AUTOSAR XML (schema 00048)
package /MICROSAR/ComM_swc
  mode declaration group ComMMode: initial-mode=COMM_NO_COMMUNICATION
    mode COMM_NO_COMMUNICATION
    mode COMM_SILENT_COMMUNICATION
    mode COMM_FULL_COMMUNICATION
  data type mapping set ComMMode_DataTypeMappingSet: mode-request-type-map{implementation-data-type=ComM_ModeType, mode-group=ComMMode}  # Data Mapping for the Mode Declaration Group ComMMode.
package /MICROSAR/ComM_swc/DataTypes
  4 x impl type, all with category=TYPE_REFERENCE:
    ComM_ModeType: compu {0=COMM_NO_COMMUNICATION, 1=COMM_SILENT_COMMUNICATION, 2=COMM_FULL_COMMUNICATION}, range raw 0..3, implementation-data-type=uint8
    ComM_InhibitionStatusType: range raw 0..255, implementation-data-type=uint8
    ComM_UserHandleType: range raw 0..65535, implementation-data-type=uint16
    NetworkHandleType: range raw 0..255, implementation-data-type=uint8, type-emitter=ComM
package /MICROSAR/ComM_swc/Interfaces
  4 x client server interface, all with is-service=true, service-kind=COM-MANAGER:
    ComM_UserRequest
      4 x operation:
        RequestComMode: possible-error=[ComM_UserRequest/E_NOT_OK, E_MODE_LIMITATION]
          arg ComMode: type=ComM_ModeType, direction=IN
        GetCurrentComMode: possible-error=ComM_UserRequest/E_NOT_OK
          arg ComMode: type=ComM_ModeType, direction=OUT
        GetMaxComMode: possible-error=ComM_UserRequest/E_NOT_OK
          arg ComMode: type=ComM_ModeType, direction=OUT
        GetRequestedComMode: possible-error=ComM_UserRequest/E_NOT_OK
          arg ComMode: type=ComM_ModeType, direction=OUT
      4 x error:
        E_NOT_OK: error-code=1
        E_MODE_LIMITATION: error-code=2
        E_MULTIPLE_PNC_ASSIGNED: error-code=4
        COMM_E_NO_PNC_ASSIGNED: error-code=5
    ComM_ECUModeLimitation
      4 x operation, all with possible-error=ComM_ECUModeLimitation/E_NOT_OK:
        LimitECUToNoComMode
          arg Status: type=boolean, direction=IN
        ReadInhibitCounter
          arg CounterValue: type=uint16, direction=OUT
        ResetInhibitCounter
        SetECUGroupClassification
          arg Status: type=ComM_InhibitionStatusType, direction=IN
      error E_NOT_OK: error-code=1
    ComM_ChannelWakeUp
      operation PreventWakeUp: possible-error=ComM_ChannelWakeUp/E_NOT_OK
        arg Status: type=boolean, direction=IN
      operation GetInhibitionStatus: possible-error=ComM_ChannelWakeUp/E_NOT_OK
        arg Status: type=ComM_InhibitionStatusType, direction=OUT
      error E_NOT_OK: error-code=1
    ComM_ChannelLimitation
      operation LimitChannelToNoComMode: possible-error=ComM_ChannelLimitation/E_NOT_OK
        arg Status: type=boolean, direction=IN
      operation GetInhibitionStatus: possible-error=ComM_ChannelLimitation/E_NOT_OK
        arg Status: type=ComM_InhibitionStatusType, direction=OUT
      error E_NOT_OK: error-code=1
  mode switch interface ComM_CurrentMode: is-service=true, service-kind=COM-MANAGER
    mode group currentMode: type=ComMMode
package /MICROSAR/ComM_swc/ComponentTypes
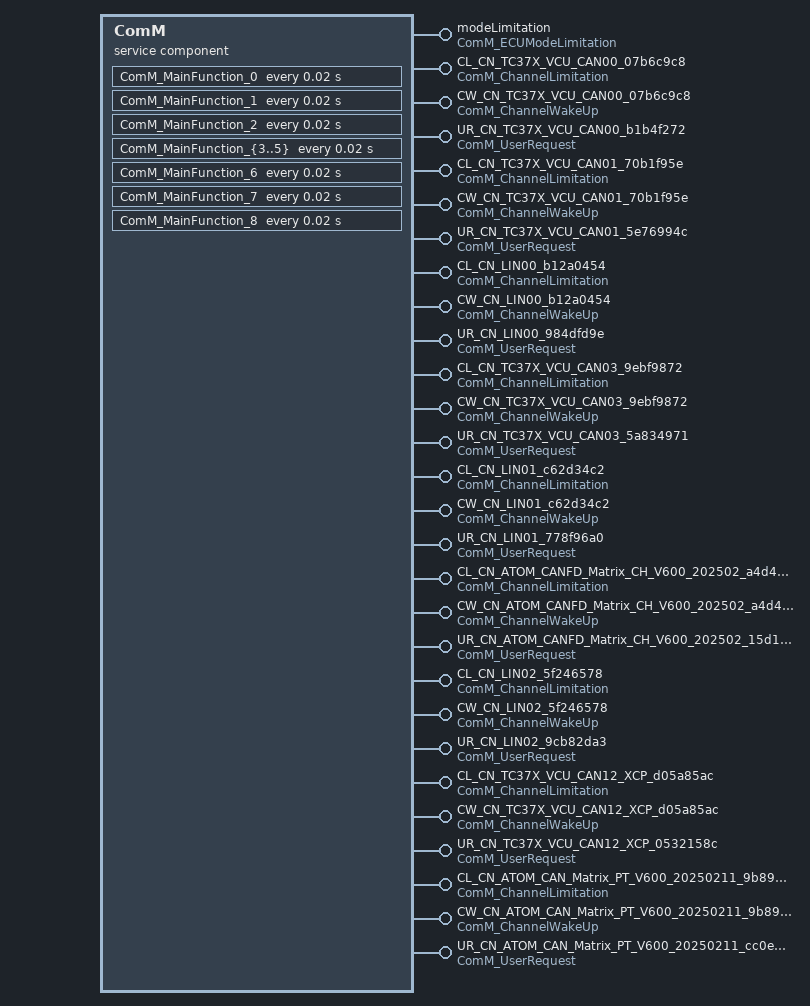
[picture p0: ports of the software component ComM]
  service sw component type ComM: category=SERVICE_COMPONENT
    28 x provide port:
      modeLimitation: provided-interface=ComM_ECUModeLimitation
      CL_CN_TC37X_VCU_CAN00_07b6c9c8: provided-interface=ComM_ChannelLimitation
      CW_CN_TC37X_VCU_CAN00_07b6c9c8: provided-interface=ComM_ChannelWakeUp
      UR_CN_TC37X_VCU_CAN00_b1b4f272: provided-interface=ComM_UserRequest
      CL_CN_TC37X_VCU_CAN01_70b1f95e: provided-interface=ComM_ChannelLimitation
      CW_CN_TC37X_VCU_CAN01_70b1f95e: provided-interface=ComM_ChannelWakeUp
      UR_CN_TC37X_VCU_CAN01_5e76994c: provided-interface=ComM_UserRequest
      CL_CN_LIN00_b12a0454: provided-interface=ComM_ChannelLimitation
      CW_CN_LIN00_b12a0454: provided-interface=ComM_ChannelWakeUp
      UR_CN_LIN00_984dfd9e: provided-interface=ComM_UserRequest
      CL_CN_TC37X_VCU_CAN03_9ebf9872: provided-interface=ComM_ChannelLimitation
      CW_CN_TC37X_VCU_CAN03_9ebf9872: provided-interface=ComM_ChannelWakeUp
      UR_CN_TC37X_VCU_CAN03_5a834971: provided-interface=ComM_UserRequest
      CL_CN_LIN01_c62d34c2: provided-interface=ComM_ChannelLimitation
      CW_CN_LIN01_c62d34c2: provided-interface=ComM_ChannelWakeUp
      UR_CN_LIN01_778f96a0: provided-interface=ComM_UserRequest
      CL_CN_ATOM_CANFD_Matrix_CH_V600_202502_a4d436ac: provided-interface=ComM_ChannelLimitation
      CW_CN_ATOM_CANFD_Matrix_CH_V600_202502_a4d436ac: provided-interface=ComM_ChannelWakeUp
      UR_CN_ATOM_CANFD_Matrix_CH_V600_202502_15d11ab0: provided-interface=ComM_UserRequest
      CL_CN_LIN02_5f246578: provided-interface=ComM_ChannelLimitation
      CW_CN_LIN02_5f246578: provided-interface=ComM_ChannelWakeUp
      UR_CN_LIN02_9cb82da3: provided-interface=ComM_UserRequest
      CL_CN_TC37X_VCU_CAN12_XCP_d05a85ac: provided-interface=ComM_ChannelLimitation
      CW_CN_TC37X_VCU_CAN12_XCP_d05a85ac: provided-interface=ComM_ChannelWakeUp
      UR_CN_TC37X_VCU_CAN12_XCP_0532158c: provided-interface=ComM_UserRequest
      CL_CN_ATOM_CAN_Matrix_PT_V600_20250211_9b894f3d: provided-interface=ComM_ChannelLimitation
      CW_CN_ATOM_CAN_Matrix_PT_V600_20250211_9b894f3d: provided-interface=ComM_ChannelWakeUp
      UR_CN_ATOM_CAN_Matrix_PT_V600_20250211_cc0efb79: provided-interface=ComM_UserRequest
    behavior ComMInternalBehavior: data-type-mapping=ComMMode_DataTypeMappingSet, handle-termination-and-restart=NO-SUPPORT, included-data-type-set=data-type=[ComM_ModeType, ComM_InhibitionStatusType, ComM_UserHandleType, NetworkHandleType]
      timing event Timer_ComM_MainFunction_0: start-on-event=ComM_MainFunction_0, period=0.02
      12 x operation invoked event:
        OpEventLimitECUToNoComMode_LimitECUToNoComMode_modeLimitation: start-on-event=LimitECUToNoComMode, operation=modeLimitation.LimitECUToNoComMode
        OpEventReadInhibitCounter_ReadInhibitCounter_modeLimitation: start-on-event=ReadInhibitCounter, operation=modeLimitation.ReadInhibitCounter
        OpEventResetInhibitCounter_ResetInhibitCounter_modeLimitation: start-on-event=ResetInhibitCounter, operation=modeLimitation.ResetInhibitCounter
        OpEventSetECUGroupClassification_SetECUGroupClassification_modeLimitation: start-on-event=SetECUGroupClassification, operation=modeLimitation.SetECUGroupClassification
        OpEventGetInhibitionStatus_GetInhibitionStatus_CL_CN_TC37X_VCU_CAN00_07b6c9c8: start-on-event=GetInhibitionStatus, operation=CL_CN_TC37X_VCU_CAN00_07b6c9c8.GetInhibitionStatus
        OpEventGetInhibitionStatus_GetInhibitionStatus_CW_CN_TC37X_VCU_CAN00_07b6c9c8: start-on-event=GetInhibitionStatus, operation=CW_CN_TC37X_VCU_CAN00_07b6c9c8.GetInhibitionStatus
        OpEventLimitChannelToNoComMode_LimitChannelToNoComMode_CL_CN_TC37X_VCU_CAN00_07b6c9c8: start-on-event=LimitChannelToNoComMode, operation=CL_CN_TC37X_VCU_CAN00_07b6c9c8.LimitChannelToNoComMode
        OpEventPreventWakeUp_PreventWakeUp_CW_CN_TC37X_VCU_CAN00_07b6c9c8: start-on-event=PreventWakeUp, operation=CW_CN_TC37X_VCU_CAN00_07b6c9c8.PreventWakeUp
        OpEventRequestComMode_RequestComMode_UR_CN_TC37X_VCU_CAN00_b1b4f272: start-on-event=RequestComMode, operation=UR_CN_TC37X_VCU_CAN00_b1b4f272.RequestComMode
        OpEventGetCurrentComMode_GetCurrentComMode_UR_CN_TC37X_VCU_CAN00_b1b4f272: start-on-event=GetCurrentComMode, operation=UR_CN_TC37X_VCU_CAN00_b1b4f272.GetCurrentComMode
        OpEventGetMaxComMode_GetMaxComMode_UR_CN_TC37X_VCU_CAN00_b1b4f272: start-on-event=GetMaxComMode, operation=UR_CN_TC37X_VCU_CAN00_b1b4f272.GetMaxComMode
        OpEventGetRequestedComMode_GetRequestedComMode_UR_CN_TC37X_VCU_CAN00_b1b4f272: start-on-event=GetRequestedComMode, operation=UR_CN_TC37X_VCU_CAN00_b1b4f272.GetRequestedComMode
      timing event Timer_ComM_MainFunction_1: start-on-event=ComM_MainFunction_1, period=0.02
      8 x operation invoked event:
        OpEventGetInhibitionStatus_GetInhibitionStatus_CL_CN_TC37X_VCU_CAN01_70b1f95e: start-on-event=GetInhibitionStatus, operation=CL_CN_TC37X_VCU_CAN01_70b1f95e.GetInhibitionStatus
        OpEventGetInhibitionStatus_GetInhibitionStatus_CW_CN_TC37X_VCU_CAN01_70b1f95e: start-on-event=GetInhibitionStatus, operation=CW_CN_TC37X_VCU_CAN01_70b1f95e.GetInhibitionStatus
        OpEventLimitChannelToNoComMode_LimitChannelToNoComMode_CL_CN_TC37X_VCU_CAN01_70b1f95e: start-on-event=LimitChannelToNoComMode, operation=CL_CN_TC37X_VCU_CAN01_70b1f95e.LimitChannelToNoComMode
        OpEventPreventWakeUp_PreventWakeUp_CW_CN_TC37X_VCU_CAN01_70b1f95e: start-on-event=PreventWakeUp, operation=CW_CN_TC37X_VCU_CAN01_70b1f95e.PreventWakeUp
        OpEventRequestComMode_RequestComMode_UR_CN_TC37X_VCU_CAN01_5e76994c: start-on-event=RequestComMode, operation=UR_CN_TC37X_VCU_CAN01_5e76994c.RequestComMode
        OpEventGetCurrentComMode_GetCurrentComMode_UR_CN_TC37X_VCU_CAN01_5e76994c: start-on-event=GetCurrentComMode, operation=UR_CN_TC37X_VCU_CAN01_5e76994c.GetCurrentComMode
        OpEventGetMaxComMode_GetMaxComMode_UR_CN_TC37X_VCU_CAN01_5e76994c: start-on-event=GetMaxComMode, operation=UR_CN_TC37X_VCU_CAN01_5e76994c.GetMaxComMode
        OpEventGetRequestedComMode_GetRequestedComMode_UR_CN_TC37X_VCU_CAN01_5e76994c: start-on-event=GetRequestedComMode, operation=UR_CN_TC37X_VCU_CAN01_5e76994c.GetRequestedComMode
      timing event Timer_ComM_MainFunction_2: start-on-event=ComM_MainFunction_2, period=0.02
      8 x operation invoked event:
        OpEventGetInhibitionStatus_GetInhibitionStatus_CL_CN_LIN00_b12a0454: start-on-event=GetInhibitionStatus, operation=CL_CN_LIN00_b12a0454.GetInhibitionStatus
        OpEventGetInhibitionStatus_GetInhibitionStatus_CW_CN_LIN00_b12a0454: start-on-event=GetInhibitionStatus, operation=CW_CN_LIN00_b12a0454.GetInhibitionStatus
        OpEventLimitChannelToNoComMode_LimitChannelToNoComMode_CL_CN_LIN00_b12a0454: start-on-event=LimitChannelToNoComMode, operation=CL_CN_LIN00_b12a0454.LimitChannelToNoComMode
        OpEventPreventWakeUp_PreventWakeUp_CW_CN_LIN00_b12a0454: start-on-event=PreventWakeUp, operation=CW_CN_LIN00_b12a0454.PreventWakeUp
        OpEventRequestComMode_RequestComMode_UR_CN_LIN00_984dfd9e: start-on-event=RequestComMode, operation=UR_CN_LIN00_984dfd9e.RequestComMode
        OpEventGetCurrentComMode_GetCurrentComMode_UR_CN_LIN00_984dfd9e: start-on-event=GetCurrentComMode, operation=UR_CN_LIN00_984dfd9e.GetCurrentComMode
        OpEventGetMaxComMode_GetMaxComMode_UR_CN_LIN00_984dfd9e: start-on-event=GetMaxComMode, operation=UR_CN_LIN00_984dfd9e.GetMaxComMode
        OpEventGetRequestedComMode_GetRequestedComMode_UR_CN_LIN00_984dfd9e: start-on-event=GetRequestedComMode, operation=UR_CN_LIN00_984dfd9e.GetRequestedComMode
      timing event Timer_ComM_MainFunction_{3..5}: start-on-event=ComM_MainFunction_{3..5}, period=0.02
      8 x operation invoked event:
        OpEventGetInhibitionStatus_GetInhibitionStatus_CL_CN_TC37X_VCU_CAN03_9ebf9872: start-on-event=GetInhibitionStatus, operation=CL_CN_TC37X_VCU_CAN03_9ebf9872.GetInhibitionStatus
        OpEventGetInhibitionStatus_GetInhibitionStatus_CW_CN_TC37X_VCU_CAN03_9ebf9872: start-on-event=GetInhibitionStatus, operation=CW_CN_TC37X_VCU_CAN03_9ebf9872.GetInhibitionStatus
        OpEventLimitChannelToNoComMode_LimitChannelToNoComMode_CL_CN_TC37X_VCU_CAN03_9ebf9872: start-on-event=LimitChannelToNoComMode, operation=CL_CN_TC37X_VCU_CAN03_9ebf9872.LimitChannelToNoComMode
        OpEventPreventWakeUp_PreventWakeUp_CW_CN_TC37X_VCU_CAN03_9ebf9872: start-on-event=PreventWakeUp, operation=CW_CN_TC37X_VCU_CAN03_9ebf9872.PreventWakeUp
        OpEventRequestComMode_RequestComMode_UR_CN_TC37X_VCU_CAN03_5a834971: start-on-event=RequestComMode, operation=UR_CN_TC37X_VCU_CAN03_5a834971.RequestComMode
        OpEventGetCurrentComMode_GetCurrentComMode_UR_CN_TC37X_VCU_CAN03_5a834971: start-on-event=GetCurrentComMode, operation=UR_CN_TC37X_VCU_CAN03_5a834971.GetCurrentComMode
        OpEventGetMaxComMode_GetMaxComMode_UR_CN_TC37X_VCU_CAN03_5a834971: start-on-event=GetMaxComMode, operation=UR_CN_TC37X_VCU_CAN03_5a834971.GetMaxComMode
        OpEventGetRequestedComMode_GetRequestedComMode_UR_CN_TC37X_VCU_CAN03_5a834971: start-on-event=GetRequestedComMode, operation=UR_CN_TC37X_VCU_CAN03_5a834971.GetRequestedComMode
      timing event Timer_ComM_MainFunction_6: start-on-event=ComM_MainFunction_6, period=0.02
      16 x operation invoked event:
        OpEventGetInhibitionStatus_GetInhibitionStatus_CL_CN_LIN01_c62d34c2: start-on-event=GetInhibitionStatus, operation=CL_CN_LIN01_c62d34c2.GetInhibitionStatus
        OpEventGetInhibitionStatus_GetInhibitionStatus_CW_CN_LIN01_c62d34c2: start-on-event=GetInhibitionStatus, operation=CW_CN_LIN01_c62d34c2.GetInhibitionStatus
        OpEventLimitChannelToNoComMode_LimitChannelToNoComMode_CL_CN_LIN01_c62d34c2: start-on-event=LimitChannelToNoComMode, operation=CL_CN_LIN01_c62d34c2.LimitChannelToNoComMode
        OpEventPreventWakeUp_PreventWakeUp_CW_CN_LIN01_c62d34c2: start-on-event=PreventWakeUp, operation=CW_CN_LIN01_c62d34c2.PreventWakeUp
        OpEventRequestComMode_RequestComMode_UR_CN_LIN01_778f96a0: start-on-event=RequestComMode, operation=UR_CN_LIN01_778f96a0.RequestComMode
        OpEventGetCurrentComMode_GetCurrentComMode_UR_CN_LIN01_778f96a0: start-on-event=GetCurrentComMode, operation=UR_CN_LIN01_778f96a0.GetCurrentComMode
        OpEventGetMaxComMode_GetMaxComMode_UR_CN_LIN01_778f96a0: start-on-event=GetMaxComMode, operation=UR_CN_LIN01_778f96a0.GetMaxComMode
        OpEventGetRequestedComMode_GetRequestedComMode_UR_CN_LIN01_778f96a0: start-on-event=GetRequestedComMode, operation=UR_CN_LIN01_778f96a0.GetRequestedComMode
        OpEventGetInhibitionStatus_GetInhibitionStatus_CL_CN_ATOM_CANFD_Matrix_CH_V600_202502_a4d436ac: start-on-event=GetInhibitionStatus, operation=CL_CN_ATOM_CANFD_Matrix_CH_V600_202502_a4d436ac.GetInhibitionStatus
        OpEventGetInhibitionStatus_GetInhibitionStatus_CW_CN_ATOM_CANFD_Matrix_CH_V600_202502_a4d436ac: start-on-event=GetInhibitionStatus, operation=CW_CN_ATOM_CANFD_Matrix_CH_V600_202502_a4d436ac.GetInhibitionStatus
        OpEventLimitChannelToNoComMode_LimitChannelToNoComMode_CL_CN_ATOM_CANFD_Matrix_CH_V600_202502_a4d436ac: start-on-event=LimitChannelToNoComMode, operation=CL_CN_ATOM_CANFD_Matrix_CH_V600_202502_a4d436ac.LimitChannelToNoComMode
        OpEventPreventWakeUp_PreventWakeUp_CW_CN_ATOM_CANFD_Matrix_CH_V600_202502_a4d436ac: start-on-event=PreventWakeUp, operation=CW_CN_ATOM_CANFD_Matrix_CH_V600_202502_a4d436ac.PreventWakeUp
        OpEventRequestComMode_RequestComMode_UR_CN_ATOM_CANFD_Matrix_CH_V600_202502_15d11ab0: start-on-event=RequestComMode, operation=UR_CN_ATOM_CANFD_Matrix_CH_V600_202502_15d11ab0.RequestComMode
        OpEventGetCurrentComMode_GetCurrentComMode_UR_CN_ATOM_CANFD_Matrix_CH_V600_202502_15d11ab0: start-on-event=GetCurrentComMode, operation=UR_CN_ATOM_CANFD_Matrix_CH_V600_202502_15d11ab0.GetCurrentComMode
        OpEventGetMaxComMode_GetMaxComMode_UR_CN_ATOM_CANFD_Matrix_CH_V600_202502_15d11ab0: start-on-event=GetMaxComMode, operation=UR_CN_ATOM_CANFD_Matrix_CH_V600_202502_15d11ab0.GetMaxComMode
        OpEventGetRequestedComMode_GetRequestedComMode_UR_CN_ATOM_CANFD_Matrix_CH_V600_202502_15d11ab0: start-on-event=GetRequestedComMode, operation=UR_CN_ATOM_CANFD_Matrix_CH_V600_202502_15d11ab0.GetRequestedComMode
      timing event Timer_ComM_MainFunction_7: start-on-event=ComM_MainFunction_7, period=0.02
      16 x operation invoked event:
        OpEventGetInhibitionStatus_GetInhibitionStatus_CL_CN_LIN02_5f246578: start-on-event=GetInhibitionStatus, operation=CL_CN_LIN02_5f246578.GetInhibitionStatus
        OpEventGetInhibitionStatus_GetInhibitionStatus_CW_CN_LIN02_5f246578: start-on-event=GetInhibitionStatus, operation=CW_CN_LIN02_5f246578.GetInhibitionStatus
        OpEventLimitChannelToNoComMode_LimitChannelToNoComMode_CL_CN_LIN02_5f246578: start-on-event=LimitChannelToNoComMode, operation=CL_CN_LIN02_5f246578.LimitChannelToNoComMode
        OpEventPreventWakeUp_PreventWakeUp_CW_CN_LIN02_5f246578: start-on-event=PreventWakeUp, operation=CW_CN_LIN02_5f246578.PreventWakeUp
        OpEventRequestComMode_RequestComMode_UR_CN_LIN02_9cb82da3: start-on-event=RequestComMode, operation=UR_CN_LIN02_9cb82da3.RequestComMode
        OpEventGetCurrentComMode_GetCurrentComMode_UR_CN_LIN02_9cb82da3: start-on-event=GetCurrentComMode, operation=UR_CN_LIN02_9cb82da3.GetCurrentComMode
        OpEventGetMaxComMode_GetMaxComMode_UR_CN_LIN02_9cb82da3: start-on-event=GetMaxComMode, operation=UR_CN_LIN02_9cb82da3.GetMaxComMode
        OpEventGetRequestedComMode_GetRequestedComMode_UR_CN_LIN02_9cb82da3: start-on-event=GetRequestedComMode, operation=UR_CN_LIN02_9cb82da3.GetRequestedComMode
        OpEventGetInhibitionStatus_GetInhibitionStatus_CL_CN_TC37X_VCU_CAN12_XCP_d05a85ac: start-on-event=GetInhibitionStatus, operation=CL_CN_TC37X_VCU_CAN12_XCP_d05a85ac.GetInhibitionStatus
        OpEventGetInhibitionStatus_GetInhibitionStatus_CW_CN_TC37X_VCU_CAN12_XCP_d05a85ac: start-on-event=GetInhibitionStatus, operation=CW_CN_TC37X_VCU_CAN12_XCP_d05a85ac.GetInhibitionStatus
        OpEventLimitChannelToNoComMode_LimitChannelToNoComMode_CL_CN_TC37X_VCU_CAN12_XCP_d05a85ac: start-on-event=LimitChannelToNoComMode, operation=CL_CN_TC37X_VCU_CAN12_XCP_d05a85ac.LimitChannelToNoComMode
        OpEventPreventWakeUp_PreventWakeUp_CW_CN_TC37X_VCU_CAN12_XCP_d05a85ac: start-on-event=PreventWakeUp, operation=CW_CN_TC37X_VCU_CAN12_XCP_d05a85ac.PreventWakeUp
        OpEventRequestComMode_RequestComMode_UR_CN_TC37X_VCU_CAN12_XCP_0532158c: start-on-event=RequestComMode, operation=UR_CN_TC37X_VCU_CAN12_XCP_0532158c.RequestComMode
        OpEventGetCurrentComMode_GetCurrentComMode_UR_CN_TC37X_VCU_CAN12_XCP_0532158c: start-on-event=GetCurrentComMode, operation=UR_CN_TC37X_VCU_CAN12_XCP_0532158c.GetCurrentComMode
        OpEventGetMaxComMode_GetMaxComMode_UR_CN_TC37X_VCU_CAN12_XCP_0532158c: start-on-event=GetMaxComMode, operation=UR_CN_TC37X_VCU_CAN12_XCP_0532158c.GetMaxComMode
        OpEventGetRequestedComMode_GetRequestedComMode_UR_CN_TC37X_VCU_CAN12_XCP_0532158c: start-on-event=GetRequestedComMode, operation=UR_CN_TC37X_VCU_CAN12_XCP_0532158c.GetRequestedComMode
      timing event Timer_ComM_MainFunction_8: start-on-event=ComM_MainFunction_8, period=0.02
      8 x operation invoked event:
        OpEventGetInhibitionStatus_GetInhibitionStatus_CL_CN_ATOM_CAN_Matrix_PT_V600_20250211_9b894f3d: start-on-event=GetInhibitionStatus, operation=CL_CN_ATOM_CAN_Matrix_PT_V600_20250211_9b894f3d.GetInhibitionStatus
        OpEventGetInhibitionStatus_GetInhibitionStatus_CW_CN_ATOM_CAN_Matrix_PT_V600_20250211_9b894f3d: start-on-event=GetInhibitionStatus, operation=CW_CN_ATOM_CAN_Matrix_PT_V600_20250211_9b894f3d.GetInhibitionStatus
        OpEventLimitChannelToNoComMode_LimitChannelToNoComMode_CL_CN_ATOM_CAN_Matrix_PT_V600_20250211_9b894f3d: start-on-event=LimitChannelToNoComMode, operation=CL_CN_ATOM_CAN_Matrix_PT_V600_20250211_9b894f3d.LimitChannelToNoComMode
        OpEventPreventWakeUp_PreventWakeUp_CW_CN_ATOM_CAN_Matrix_PT_V600_20250211_9b894f3d: start-on-event=PreventWakeUp, operation=CW_CN_ATOM_CAN_Matrix_PT_V600_20250211_9b894f3d.PreventWakeUp
        OpEventRequestComMode_RequestComMode_UR_CN_ATOM_CAN_Matrix_PT_V600_20250211_cc0efb79: start-on-event=RequestComMode, operation=UR_CN_ATOM_CAN_Matrix_PT_V600_20250211_cc0efb79.RequestComMode
        OpEventGetCurrentComMode_GetCurrentComMode_UR_CN_ATOM_CAN_Matrix_PT_V600_20250211_cc0efb79: start-on-event=GetCurrentComMode, operation=UR_CN_ATOM_CAN_Matrix_PT_V600_20250211_cc0efb79.GetCurrentComMode
        OpEventGetMaxComMode_GetMaxComMode_UR_CN_ATOM_CAN_Matrix_PT_V600_20250211_cc0efb79: start-on-event=GetMaxComMode, operation=UR_CN_ATOM_CAN_Matrix_PT_V600_20250211_cc0efb79.GetMaxComMode
        OpEventGetRequestedComMode_GetRequestedComMode_UR_CN_ATOM_CAN_Matrix_PT_V600_20250211_cc0efb79: start-on-event=GetRequestedComMode, operation=UR_CN_ATOM_CAN_Matrix_PT_V600_20250211_cc0efb79.GetRequestedComMode
      port-api-options:
        enable-take-address=true, indirect-api=false, port=modeLimitation
        {enable-take-address=true, indirect-api=false, port-defined-argument-value{value=0, value-type=NetworkHandleType}, port=CL_CN_ATOM_CANFD_Matrix_CH_V600_202502_a4d436ac}
        {enable-take-address=true, indirect-api=false, port-defined-argument-value{value=0, value-type=NetworkHandleType}, port=CW_CN_ATOM_CANFD_Matrix_CH_V600_202502_a4d436ac}
        {enable-take-address=true, indirect-api=false, port-defined-argument-value{value=0, value-type=ComM_UserHandleType}, port=UR_CN_ATOM_CANFD_Matrix_CH_V600_202502_15d11ab0}
        {enable-take-address=true, indirect-api=false, port-defined-argument-value{value=1, value-type=NetworkHandleType}, port=CL_CN_ATOM_CAN_Matrix_PT_V600_20250211_9b894f3d}
        {enable-take-address=true, indirect-api=false, port-defined-argument-value{value=1, value-type=NetworkHandleType}, port=CW_CN_ATOM_CAN_Matrix_PT_V600_20250211_9b894f3d}
        {enable-take-address=true, indirect-api=false, port-defined-argument-value{value=2, value-type=NetworkHandleType}, port=CL_CN_TC37X_VCU_CAN00_07b6c9c8}
        {enable-take-address=true, indirect-api=false, port-defined-argument-value{value=2, value-type=NetworkHandleType}, port=CW_CN_TC37X_VCU_CAN00_07b6c9c8}
        {enable-take-address=true, indirect-api=false, port-defined-argument-value{value=3, value-type=NetworkHandleType}, port=CL_CN_TC37X_VCU_CAN01_70b1f95e}
        {enable-take-address=true, indirect-api=false, port-defined-argument-value{value=3, value-type=NetworkHandleType}, port=CW_CN_TC37X_VCU_CAN01_70b1f95e}
        {enable-take-address=true, indirect-api=false, port-defined-argument-value{value=4, value-type=NetworkHandleType}, port=CL_CN_TC37X_VCU_CAN03_9ebf9872}
        {enable-take-address=true, indirect-api=false, port-defined-argument-value{value=4, value-type=NetworkHandleType}, port=CW_CN_TC37X_VCU_CAN03_9ebf9872}
        {enable-take-address=true, indirect-api=false, port-defined-argument-value{value=5, value-type=NetworkHandleType}, port=CL_CN_TC37X_VCU_CAN12_XCP_d05a85ac}
        {enable-take-address=true, indirect-api=false, port-defined-argument-value{value=5, value-type=NetworkHandleType}, port=CW_CN_TC37X_VCU_CAN12_XCP_d05a85ac}
        {enable-take-address=true, indirect-api=false, port-defined-argument-value{value=6, value-type=NetworkHandleType}, port=CL_CN_LIN00_b12a0454}
        {enable-take-address=true, indirect-api=false, port-defined-argument-value{value=6, value-type=NetworkHandleType}, port=CW_CN_LIN00_b12a0454}
        {enable-take-address=true, indirect-api=false, port-defined-argument-value{value=7, value-type=NetworkHandleType}, port=CL_CN_LIN01_c62d34c2}
        {enable-take-address=true, indirect-api=false, port-defined-argument-value{value=7, value-type=NetworkHandleType}, port=CW_CN_LIN01_c62d34c2}
        {enable-take-address=true, indirect-api=false, port-defined-argument-value{value=8, value-type=NetworkHandleType}, port=CL_CN_LIN02_5f246578}
        {enable-take-address=true, indirect-api=false, port-defined-argument-value{value=8, value-type=NetworkHandleType}, port=CW_CN_LIN02_5f246578}
        {enable-take-address=true, indirect-api=false, port-defined-argument-value{value=1, value-type=ComM_UserHandleType}, port=UR_CN_ATOM_CAN_Matrix_PT_V600_20250211_cc0efb79}
        {enable-take-address=true, indirect-api=false, port-defined-argument-value{value=6, value-type=ComM_UserHandleType}, port=UR_CN_LIN00_984dfd9e}
        {enable-take-address=true, indirect-api=false, port-defined-argument-value{value=7, value-type=ComM_UserHandleType}, port=UR_CN_LIN01_778f96a0}
        {enable-take-address=true, indirect-api=false, port-defined-argument-value{value=8, value-type=ComM_UserHandleType}, port=UR_CN_LIN02_9cb82da3}
        {enable-take-address=true, indirect-api=false, port-defined-argument-value{value=2, value-type=ComM_UserHandleType}, port=UR_CN_TC37X_VCU_CAN00_b1b4f272}
        {enable-take-address=true, indirect-api=false, port-defined-argument-value{value=3, value-type=ComM_UserHandleType}, port=UR_CN_TC37X_VCU_CAN01_5e76994c}
        {enable-take-address=true, indirect-api=false, port-defined-argument-value{value=4, value-type=ComM_UserHandleType}, port=UR_CN_TC37X_VCU_CAN03_5a834971}
        {enable-take-address=true, indirect-api=false, port-defined-argument-value{value=5, value-type=ComM_UserHandleType}, port=UR_CN_TC37X_VCU_CAN12_XCP_0532158c}
      20 x runnable, all with can-be-invoked-concurrently=true:
        ComM_MainFunction_0
        GetInhibitionStatus: symbol=ComM_GetInhibitionStatus
        LimitECUToNoComMode: symbol=ComM_LimitECUToNoComMode
        ReadInhibitCounter: symbol=ComM_ReadInhibitCounter
        ResetInhibitCounter: symbol=ComM_ResetInhibitCounter
        SetECUGroupClassification: symbol=ComM_SetECUGroupClassification
        LimitChannelToNoComMode: symbol=ComM_LimitChannelToNoComMode
        PreventWakeUp: symbol=ComM_PreventWakeUp
        RequestComMode: symbol=ComM_RequestComMode
        GetCurrentComMode: symbol=ComM_GetCurrentComMode
        GetMaxComMode: symbol=ComM_GetMaxComMode
        GetRequestedComMode: symbol=ComM_GetRequestedComMode
        ComM_MainFunction_{1..8}
  swc implementation ComMImplementation: programming-language=C, behavior=ComMInternalBehavior
